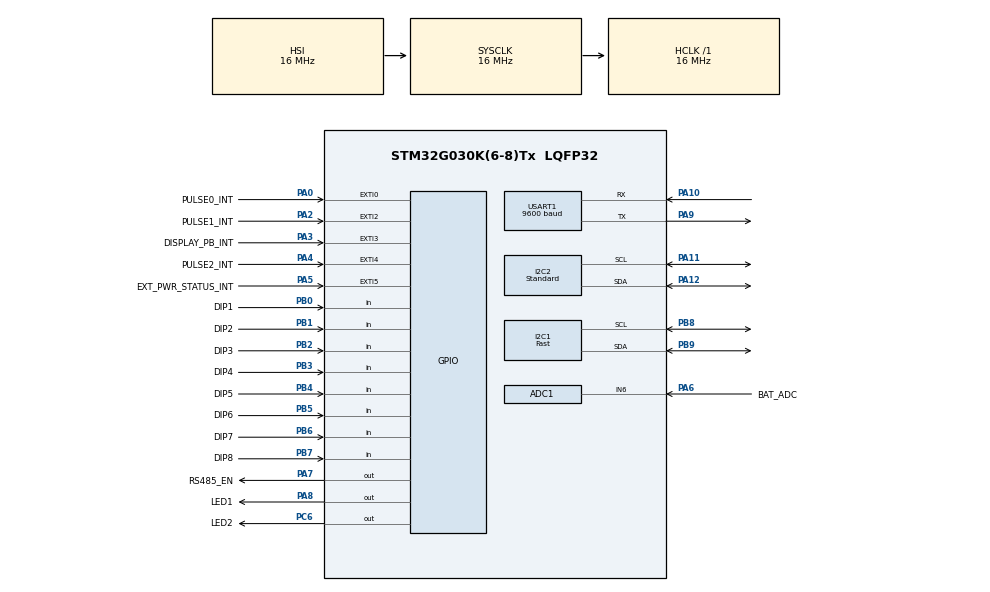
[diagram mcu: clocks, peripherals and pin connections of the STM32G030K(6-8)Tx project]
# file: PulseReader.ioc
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ADC1.Channel-1\#ChannelRegularConversion=ADC_CHANNEL_6
ADC1.NbrOfConversionFlag=1
ADC1.Overrun=ADC_OVR_DATA_PRESERVED
ADC1.Rank-1\#ChannelRegularConversion=1
ADC1.SamplingTime-1\#ChannelRegularConversion=ADC_SAMPLINGTIME_COMMON_1
ADC1.SamplingTimeCommon1=ADC_SAMPLETIME_79CYCLES_5
ADC1.SamplingTimeCommon2=ADC_SAMPLETIME_79CYCLES_5
ADC1.SelectedChannel=ADC_CHANNEL_6
ADC1.master=1
I2C1.I2C_Speed_Mode=I2C_Fast
I2C1.Timing=0x00300617
I2C2.I2C_Speed_Mode=I2C_Standard
I2C2.Timing=0x00503D58
Mcu.Family=STM32G0
Mcu.Name=STM32G030K(6-8)Tx
Mcu.Package=LQFP32
NVIC.EXTI0_1_IRQn=true\:0\:0\:false\:false\:true\:true\:true\:true
NVIC.EXTI2_3_IRQn=true\:0\:0\:false\:false\:true\:true\:true\:true
NVIC.EXTI4_15_IRQn=true\:0\:0\:false\:false\:true\:true\:true\:true
NVIC.RTC_TAMP_IRQn=true\:0\:0\:false\:false\:true\:true\:true\:true
NVIC.USART1_IRQn=true\:2\:0\:true\:false\:true\:true\:true\:true
PA0.GPIO_Label=PULSE0_INT
PA0.GPIO_ModeDefaultEXTI=GPIO_MODE_IT_RISING_FALLING
PA0.Signal=GPXTI0
PA10.Mode=Asynchronous
PA10.Signal=USART1_RX
PA11\ [PA9].Mode=I2C
PA11\ [PA9].Signal=I2C2_SCL
PA12\ [PA10].Mode=I2C
PA12\ [PA10].Signal=I2C2_SDA
PA13.Mode=Serial_Wire
PA13.Signal=SYS_SWDIO
PA14-BOOT0.Mode=Serial_Wire
PA14-BOOT0.Signal=SYS_SWCLK
PA2.GPIO_Label=PULSE1_INT
PA2.GPIO_ModeDefaultEXTI=GPIO_MODE_IT_RISING_FALLING
PA2.Signal=GPXTI2
PA3.GPIO_Label=DISPLAY_PB_INT
PA3.GPIO_ModeDefaultEXTI=GPIO_MODE_IT_RISING_FALLING
PA3.Signal=GPXTI3
PA4.GPIO_Label=PULSE2_INT
PA4.GPIO_ModeDefaultEXTI=GPIO_MODE_IT_RISING_FALLING
PA4.Signal=GPXTI4
PA5.GPIO_Label=EXT_PWR_STATUS_INT
PA5.GPIO_ModeDefaultEXTI=GPIO_MODE_IT_RISING_FALLING
PA5.Signal=GPXTI5
PA6.GPIO_Label=BAT_ADC
PA6.Mode=IN6
PA6.Signal=ADC1_IN6
PA7.GPIO_Label=RS485_EN
PA7.Signal=GPIO_Output
PA8.GPIO_Label=LED1
PA8.Signal=GPIO_Output
PA9.Mode=Asynchronous
PA9.Signal=USART1_TX
PB0.GPIO_Label=DIP1
PB0.Signal=GPIO_Input
PB1.GPIO_Label=DIP2
PB1.Signal=GPIO_Input
PB2.GPIO_Label=DIP3
PB2.Signal=GPIO_Input
PB3.GPIO_Label=DIP4
PB3.Signal=GPIO_Input
PB4.GPIO_Label=DIP5
PB4.Signal=GPIO_Input
PB5.GPIO_Label=DIP6
PB5.Signal=GPIO_Input
PB6.GPIO_Label=DIP7
PB6.Signal=GPIO_Input
PB7.GPIO_Label=DIP8
PB7.Signal=GPIO_Input
PB8.Mode=I2C
PB8.Signal=I2C1_SCL
PB9.Mode=I2C
PB9.Signal=I2C1_SDA
PC14-OSC32_IN\ (PC14).Mode=LSE-External-Oscillator
PC14-OSC32_IN\ (PC14).Signal=RCC_OSC32_IN
PC15-OSC32_OUT\ (PC15).Mode=LSE-External-Oscillator
PC15-OSC32_OUT\ (PC15).Signal=RCC_OSC32_OUT
PC6.GPIO_Label=LED2
PC6.Signal=GPIO_Output
ProjectManager.HeapSize=0x200
ProjectManager.StackSize=0x400
ProjectManager.TargetToolchain=STM32CubeIDE
RCC.ADCFreq_Value=16000000
RCC.AHBFreq_Value=16000000
RCC.CortexFreq_Value=16000000
RCC.EXTERNAL_CLOCK_VALUE=12288000
RCC.HCLKFreq_Value=16000000
RCC.HSE_VALUE=8000000
RCC.HSI_VALUE=16000000
RCC.RTCClockSelection=RCC_RTCCLKSOURCE_LSE
RCC.SYSCLKFreq_VALUE=16000000
RCC.VCOOutputFreq_Value=128000000
RTC.Alarm-Alarm\ A=RTC_ALARM_A
USART1.BaudRate=9600
USART1.DMADisableonRxErrorParam=ADVFEATURE_DMA_DISABLEONRXERROR
USART1.OverrunDisableParam=ADVFEATURE_OVERRUN_DISABLE
USART1.VirtualMode-Asynchronous=VM_ASYNC
VP_RTC_VS_RTC_Activate.Mode=RTC_Enabled
VP_RTC_VS_RTC_Alarm_A_Intern.Mode=Alarm A
VP_RTC_VS_RTC_Calendar.Mode=RTC_Calendar
board=custom

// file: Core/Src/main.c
/* USER CODE BEGIN Header */
/**
  ******************************************************************************
  * @file           : main.c
  * @brief          : Main program body
  ******************************************************************************
  * @attention
  *
  * Copyright (c) 2026 STMicroelectronics.
  * All rights reserved.
  *
  * This software is licensed under terms that can be found in the LICENSE file
  * in the root directory of this software component.
  * If no LICENSE file comes with this software, it is provided AS-IS.
  *
  ******************************************************************************
  */
/* USER CODE END Header */
#include "main.h"
#include "adc.h"
#include "i2c.h"
#include "rtc.h"
#include "usart.h"
#include "gpio.h"

void SystemClock_Config(void);
/* USER CODE BEGIN PFP */
#include "application.h"
/* USER CODE END PFP */

int main(void)
{

  /* MCU Configuration--------------------------------------------------------*/

  /* Reset of all peripherals, Initializes the Flash interface and the Systick. */
  HAL_Init();

  /* Configure the system clock */
  SystemClock_Config();

  /* Initialize all configured peripherals */
  MX_GPIO_Init();
  MX_ADC1_Init();
  MX_I2C1_Init();
  MX_I2C2_Init();
  MX_USART1_UART_Init();
  MX_RTC_Init();

  /* Infinite loop */
  /* USER CODE BEGIN WHILE */
  initialize_application();
  while (1)
  {
	  process_application();
    /* USER CODE END WHILE */

  }
}

void SystemClock_Config(void)
{
  RCC_OscInitTypeDef RCC_OscInitStruct = {0};
  RCC_ClkInitTypeDef RCC_ClkInitStruct = {0};

  /** Configure the main internal regulator output voltage
  */
  HAL_PWREx_ControlVoltageScaling(PWR_REGULATOR_VOLTAGE_SCALE1);

  /** Configure LSE Drive Capability
  */
  HAL_PWR_EnableBkUpAccess();
  __HAL_RCC_LSEDRIVE_CONFIG(RCC_LSEDRIVE_LOW);

  /** Initializes the RCC Oscillators according to the specified parameters
  * in the RCC_OscInitTypeDef structure.
  */
  RCC_OscInitStruct.OscillatorType = RCC_OSCILLATORTYPE_HSI|RCC_OSCILLATORTYPE_LSE;
  RCC_OscInitStruct.LSEState = RCC_LSE_ON;
  RCC_OscInitStruct.HSIState = RCC_HSI_ON;
  RCC_OscInitStruct.HSIDiv = RCC_HSI_DIV1;
  RCC_OscInitStruct.HSICalibrationValue = RCC_HSICALIBRATION_DEFAULT;
  RCC_OscInitStruct.PLL.PLLState = RCC_PLL_NONE;
  if (HAL_RCC_OscConfig(&RCC_OscInitStruct) != HAL_OK)
  {
    Error_Handler();
  }

  /** Initializes the CPU, AHB and APB buses clocks
  */
  RCC_ClkInitStruct.ClockType = RCC_CLOCKTYPE_HCLK|RCC_CLOCKTYPE_SYSCLK
                              |RCC_CLOCKTYPE_PCLK1;
  RCC_ClkInitStruct.SYSCLKSource = RCC_SYSCLKSOURCE_HSI;
  RCC_ClkInitStruct.AHBCLKDivider = RCC_SYSCLK_DIV1;
  RCC_ClkInitStruct.APB1CLKDivider = RCC_HCLK_DIV1;

  if (HAL_RCC_ClockConfig(&RCC_ClkInitStruct, FLASH_LATENCY_0) != HAL_OK)
  {
    Error_Handler();
  }
}

void Error_Handler(void)
{
  __disable_irq();
  while (1)
  {
  }
}
